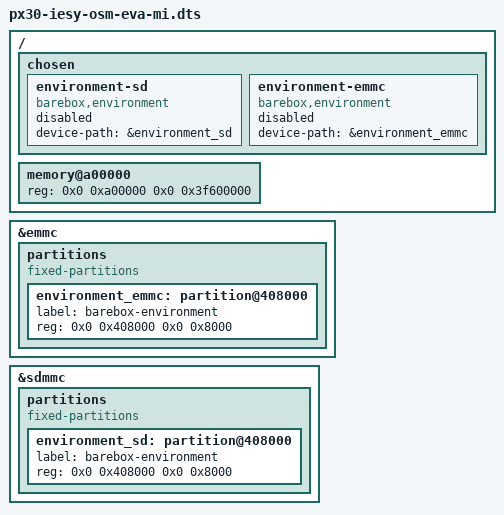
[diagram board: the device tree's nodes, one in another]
// SPDX-License-Identifier: (GPL-2.0+ OR MIT)
/*
 * Copyright (c) 2022 Ahmad Fatoum, Pengutronix
 */

#include "px30-iesy-osm-eva-mi.dtsi"
#include "px30.dtsi"

/ {
	chosen {
		environment-sd {
			compatible = "barebox,environment";
			device-path = &environment_sd;
			status = "disabled";
		};

		environment-emmc {
			compatible = "barebox,environment";
			device-path = &environment_emmc;
			status = "disabled";
		};
	};

	memory@a00000 {
		device_type = "memory";
		reg = <0x0 0xa00000 0x0 0x3f600000>;
	};
};

&emmc {
	partitions {
		compatible = "fixed-partitions";
		#address-cells = <2>;
		#size-cells = <2>;

		environment_emmc: partition@408000 {
			label = "barebox-environment";
			reg = <0x0 0x408000 0x0 0x8000>;
		};
	};
};

&sdmmc {
	partitions {
		compatible = "fixed-partitions";
		#address-cells = <2>;
		#size-cells = <2>;

		environment_sd: partition@408000 {
			label = "barebox-environment";
			reg = <0x0 0x408000 0x0 0x8000>;
		};
	};
};
